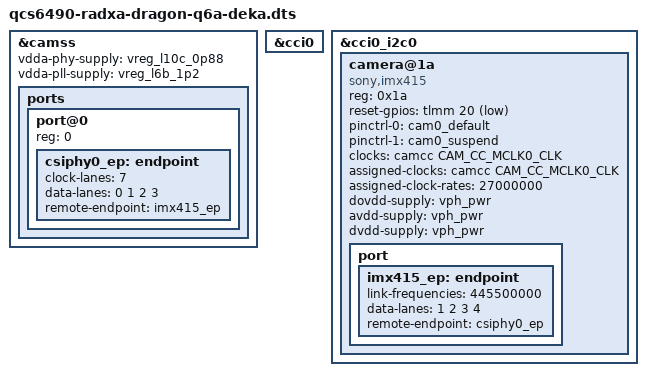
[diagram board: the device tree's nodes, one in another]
/dts-v1/;

#include "qcs6490-radxa-dragon-q6a.dtsi"

&camss {
	vdda-phy-supply = <&vreg_l10c_0p88>;
	vdda-pll-supply = <&vreg_l6b_1p2>;

	status = "okay";

	ports {
		#address-cells = <1>;
		#size-cells = <0>;

		/* The port index denotes CSIPHY id i.e. csiphy0 */
		port@0 {
			reg = <0>;

			csiphy0_ep: endpoint {
				clock-lanes = <7>;
				data-lanes = <0 1 2 3>;
				remote-endpoint = <&imx415_ep>;
			};
		};
	};
};


&cci0 {
	status = "okay";
};

&cci0_i2c0 {
	#address-cells = <1>;
	#size-cells = <0>;

	camera@1a {
		compatible = "sony,imx415";

		reg = <0x1a>;

		reset-gpios = <&tlmm 20 GPIO_ACTIVE_LOW>;
		pinctrl-names = "default", "suspend";
		pinctrl-0 = <&cam0_default>;
		pinctrl-1 = <&cam0_suspend>;

		clocks = <&camcc CAM_CC_MCLK0_CLK>;
		clock-names = "inck";
		assigned-clocks = <&camcc CAM_CC_MCLK0_CLK>;
		assigned-clock-rates = <27000000>;

		dovdd-supply = <&vph_pwr>;
		avdd-supply = <&vph_pwr>;
		dvdd-supply = <&vph_pwr>;

		port {
			imx415_ep: endpoint {
				link-frequencies = /bits/ 64 <445500000>;
				data-lanes = <1 2 3 4>;
				remote-endpoint = <&csiphy0_ep>;
			};
		};
	};
};

